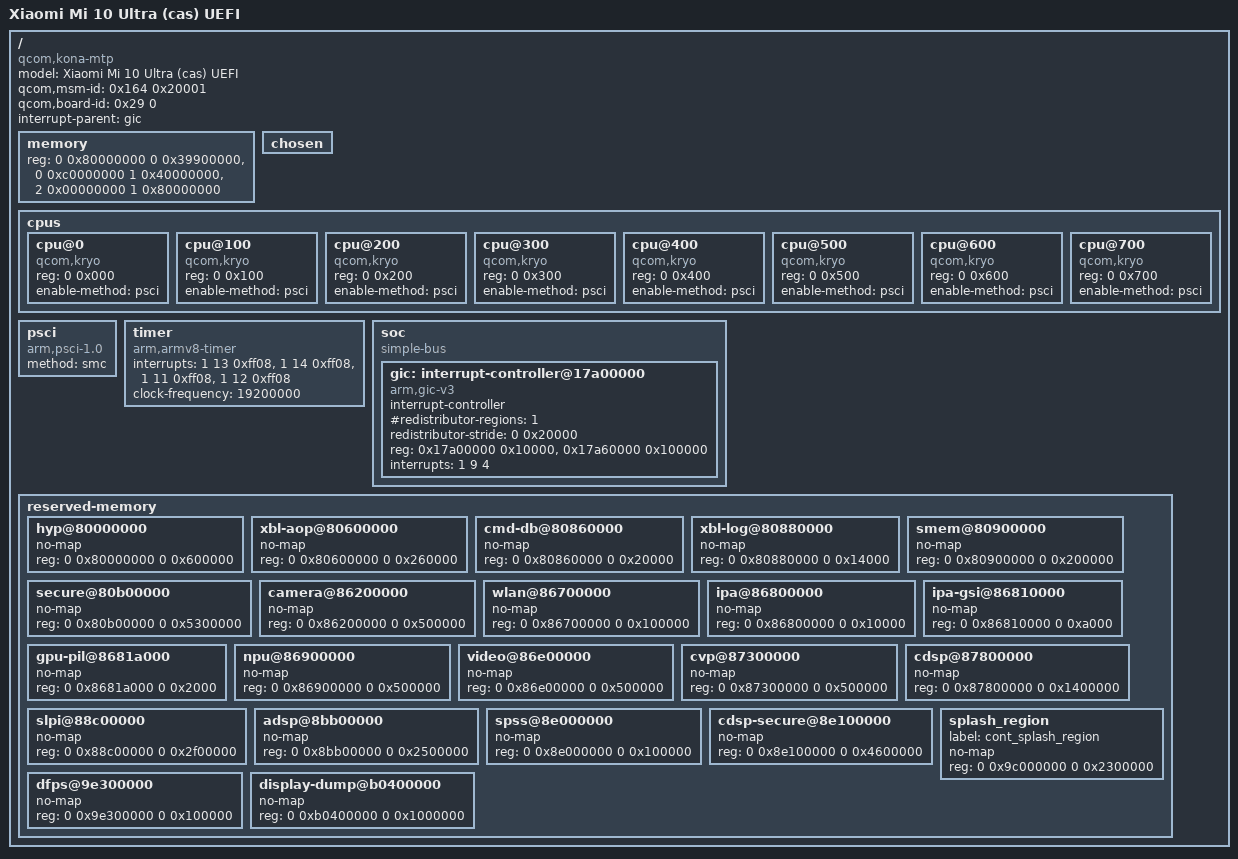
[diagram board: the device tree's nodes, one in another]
// SPDX-License-Identifier: BSD-2-Clause-Patent
// Xiaomi Mi 10 Ultra / cas. Facts: captured boot DTB 2 + DTBO 26 and live FDT.
// Historical cas-base-001/002 tree: stock ABL DTBO overlay rejected it.
// Current packaging uses the hash-pinned stock SoC DTB in cas.toml instead.
// ABL fills /chosen and /memory at boot; never copy an Android bootargs/seed.
/dts-v1/;

/ {
    model = "Xiaomi Mi 10 Ultra (cas) UEFI";
    compatible = "qcom,kona-mtp", "qcom,kona", "qcom,mtp";
    qcom,msm-id = <0x164 0x20001>;
    qcom,board-id = <0x29 0>;
    #address-cells = <2>;
    #size-cells = <2>;
    interrupt-parent = <&gic>;

    // Exact /memory name is consumed by this ABL. Values describe this 12 GB
    // device only; they do not grant the UEFI allocator access to all RAM.
    memory {
        device_type = "memory";
        reg = <0 0x80000000 0 0x39900000>,
              <0 0xc0000000 1 0x40000000>,
              <2 0x00000000 1 0x80000000>;
    };

    chosen {};

    cpus {
        #address-cells = <2>;
        #size-cells = <0>;
        cpu@0   { device_type = "cpu"; compatible = "qcom,kryo"; reg = <0 0x000>; enable-method = "psci"; };
        cpu@100 { device_type = "cpu"; compatible = "qcom,kryo"; reg = <0 0x100>; enable-method = "psci"; };
        cpu@200 { device_type = "cpu"; compatible = "qcom,kryo"; reg = <0 0x200>; enable-method = "psci"; };
        cpu@300 { device_type = "cpu"; compatible = "qcom,kryo"; reg = <0 0x300>; enable-method = "psci"; };
        cpu@400 { device_type = "cpu"; compatible = "qcom,kryo"; reg = <0 0x400>; enable-method = "psci"; };
        cpu@500 { device_type = "cpu"; compatible = "qcom,kryo"; reg = <0 0x500>; enable-method = "psci"; };
        cpu@600 { device_type = "cpu"; compatible = "qcom,kryo"; reg = <0 0x600>; enable-method = "psci"; };
        cpu@700 { device_type = "cpu"; compatible = "qcom,kryo"; reg = <0 0x700>; enable-method = "psci"; };
    };

    psci { compatible = "arm,psci-1.0"; method = "smc"; };

    timer {
        compatible = "arm,armv8-timer";
        interrupts = <1 13 0xff08>, <1 14 0xff08>, <1 11 0xff08>, <1 12 0xff08>;
        clock-frequency = <19200000>;
    };

    soc {
        compatible = "simple-bus";
        #address-cells = <1>;
        #size-cells = <1>;
        ranges = <0 0 0 0x40000000>;

        gic: interrupt-controller@17a00000 {
            compatible = "arm,gic-v3";
            #address-cells = <0>;
            #interrupt-cells = <3>;
            interrupt-controller;
            #redistributor-regions = <1>;
            redistributor-stride = <0 0x20000>;
            reg = <0x17a00000 0x10000>, <0x17a60000 0x100000>;
            interrupts = <1 9 4>;
        };
    };

    // Keep every fixed reservation from the captured tree. Android-only
    // dynamic CMA requests are omitted: there is no Android allocator here.
    reserved-memory {
        #address-cells = <2>;
        #size-cells = <2>;
        ranges;
        hyp@80000000 { no-map; reg = <0 0x80000000 0 0x600000>; };
        xbl-aop@80600000 { no-map; reg = <0 0x80600000 0 0x260000>; };
        cmd-db@80860000 { no-map; reg = <0 0x80860000 0 0x20000>; };
        xbl-log@80880000 { no-map; reg = <0 0x80880000 0 0x14000>; };
        smem@80900000 { no-map; reg = <0 0x80900000 0 0x200000>; };
        secure@80b00000 { no-map; reg = <0 0x80b00000 0 0x5300000>; };
        camera@86200000 { no-map; reg = <0 0x86200000 0 0x500000>; };
        wlan@86700000 { no-map; reg = <0 0x86700000 0 0x100000>; };
        ipa@86800000 { no-map; reg = <0 0x86800000 0 0x10000>; };
        ipa-gsi@86810000 { no-map; reg = <0 0x86810000 0 0xa000>; };
        gpu-pil@8681a000 { no-map; reg = <0 0x8681a000 0 0x2000>; };
        npu@86900000 { no-map; reg = <0 0x86900000 0 0x500000>; };
        video@86e00000 { no-map; reg = <0 0x86e00000 0 0x500000>; };
        cvp@87300000 { no-map; reg = <0 0x87300000 0 0x500000>; };
        cdsp@87800000 { no-map; reg = <0 0x87800000 0 0x1400000>; };
        slpi@88c00000 { no-map; reg = <0 0x88c00000 0 0x2f00000>; };
        adsp@8bb00000 { no-map; reg = <0 0x8bb00000 0 0x2500000>; };
        spss@8e000000 { no-map; reg = <0 0x8e000000 0 0x100000>; };
        cdsp-secure@8e100000 { no-map; reg = <0 0x8e100000 0 0x4600000>; };

        // The exact path and 4-cell reg length are present in cas ABL code
        // (LinuxLoader RVA 0x1cb28..0x1ccac). ABL may replace the base/size.
        // This reservation is NOT proof of scanout address/stride/format.
        splash_region {
            label = "cont_splash_region";
            no-map;
            reg = <0 0x9c000000 0 0x2300000>;
        };
        dfps@9e300000 { no-map; reg = <0 0x9e300000 0 0x100000>; };
        display-dump@b0400000 { no-map; reg = <0 0xb0400000 0 0x1000000>; };
    };
};
